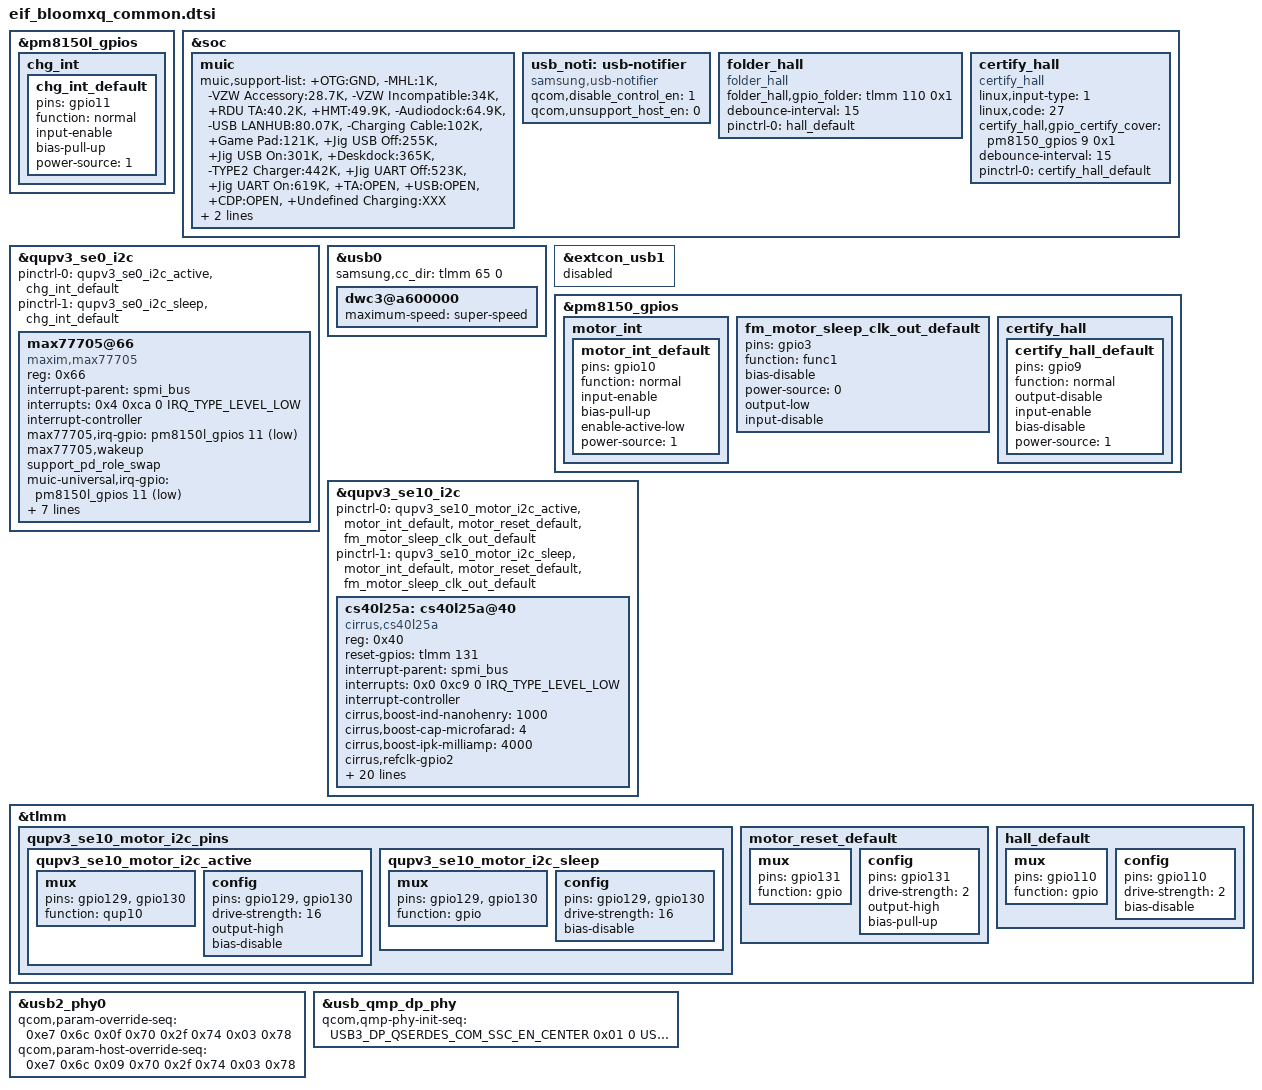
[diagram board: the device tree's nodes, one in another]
/* Copyright (c) 2019, The Linux Foundation. All rights reserved.
 *
 * This program is free software; you can redistribute it and/or modify
 * it under the terms of the GNU General Public License version 2 and
 * only version 2 as published by the Free Software Foundation.
 *
 * This program is distributed in the hope that it will be useful,
 * but WITHOUT ANY WARRANTY; without even the implied warranty of
 * MERCHANTABILITY or FITNESS FOR A PARTICULAR PURPOSE.  See the
 * GNU General Public License for more details.
 */

/* MUIC */
&pm8150l_gpios {
	chg_int {
		chg_int_default: chg_int_default {
			pins = "gpio11";
			function = "normal";
			input-enable;
			bias-pull-up;
			power-source = <1>;
		};
	};
};

&soc {
	muic {
		status = "okay";
		muic,support-list = "+OTG:GND",
				"-MHL:1K",
				"-VZW Accessory:28.7K",
				"-VZW Incompatible:34K",
				"+RDU TA:40.2K",
				"+HMT:49.9K",
				"-Audiodock:64.9K",
				"-USB LANHUB:80.07K",
				"-Charging Cable:102K",
				"+Game Pad:121K",
				"+Jig USB Off:255K",
				"+Jig USB On:301K",
				"+Deskdock:365K",
				"-TYPE2 Charger:442K",
				"+Jig UART Off:523K",
				"+Jig UART On:619K",
				"+TA:OPEN",
				"+USB:OPEN",
				"+CDP:OPEN",
				"+Undefined Charging:XXX";
		muic,afcmode-tx = /bits/ 8 <0x46>;
		muic,qc-hv = /bits/ 8 <0x9>;
	};

	usb_noti: usb-notifier {
		compatible = "samsung,usb-notifier";
		qcom,disable_control_en = <1>;
		qcom,unsupport_host_en = <0>;
	};

	folder_hall {
		compatible = "folder_hall";
		folder_hall,gpio_folder = <&tlmm 110 0x1>;
		debounce-interval = <15>;
		pinctrl-names = "default";
		pinctrl-0 = <&hall_default>;
	};

	certify_hall: certify_hall {
		status = "okay";
		compatible = "certify_hall";
		linux,input-type = <1>;
		linux,code = <27>;
		certify_hall,gpio_certify_cover = <&pm8150_gpios 9 0x1>;
		debounce-interval = <15>;
		pinctrl-names = "default";
		pinctrl-0 = <&certify_hall_default>;
	};
};

&qupv3_se0_i2c {
	status = "ok";

	pinctrl-0 = <&qupv3_se0_i2c_active &chg_int_default>;
	pinctrl-1 = <&qupv3_se0_i2c_sleep &chg_int_default>;

	max77705@66 {
		compatible = "maxim,max77705";
		reg = <0x66>;
		interrupt-parent = <&spmi_bus>;
		interrupts = <0x4 0xca 0 IRQ_TYPE_LEVEL_LOW>;
		interrupt-names = "max77705_irq";
		interrupt-controller;
		max77705,irq-gpio = <&pm8150l_gpios 11 0x01>;
		max77705,wakeup;
		support_pd_role_swap;
		muic-universal,irq-gpio = <&pm8150l_gpios 11 0x01>;
		muic-universal,chip_name = "maxim,max77705";
		muic,undefined_range;
		haptic,mode = <1>;
		haptic,divisor = <128>;
		max77705,detect-alalog-audio;
		max77705,bc1p2_retry_count = <2>;
		max77705,blocking_waterevent;
	};
};

/* USB */
&usb0 {
	samsung,cc_dir = <&tlmm 65 0>;
};

/* VIBRATOR */

/*disable extcon_usb1 because of pm8150_gpio 10 conflict*/
&extcon_usb1 {
	status = "disabled";
};

&pm8150_gpios {
	motor_int {
		motor_int_default: motor_int_default {
			pins = "gpio10";
			function = "normal";
			input-enable;
			bias-pull-up;
			enable-active-low;
			power-source = <1>;
		};
	};

	fm_motor_sleep_clk_out_default: fm_motor_sleep_clk_out_default {
		pins = "gpio3";
		function = "func1";
		bias-disable;
		power-source = <0>;
		output-low;
		input-disable;
	};
};

&qupv3_se10_i2c {
	status = "okay";
	pinctrl-names = "default", "sleep";
	pinctrl-0 = <&qupv3_se10_motor_i2c_active
			&motor_int_default &motor_reset_default
			&fm_motor_sleep_clk_out_default>;
	pinctrl-1 = <&qupv3_se10_motor_i2c_sleep &motor_int_default
			&motor_reset_default
			&fm_motor_sleep_clk_out_default>;

	cs40l25a: cs40l25a@40 {
		status = "okay";
		compatible = "cirrus,cs40l25a";
		reg = <0x40>;
		reset-gpios = <&tlmm 131 0>; // MOTOR_RST
		interrupt-parent = <&spmi_bus>;
		interrupts = <0x0 0xc9 0 IRQ_TYPE_LEVEL_LOW>; // MOTOR_INT
		interrupt-names = "default";
		interrupt-controller;
		cirrus,boost-ind-nanohenry = <1000>;
		cirrus,boost-cap-microfarad = <4>;
		cirrus,boost-ipk-milliamp = <4000>;
		cirrus,refclk-gpio2;
		cirrus,auto-recovery;
		cirrus,amp-gnd-stby;
		cirrus,hiber-enable;
		cirrus,gpio-indv-enable = <0x4>;
		cirrus,gpio1-mode = <1>;
		cirrus,boost-clab-millivolt = <4900>;
		cirrus,fw-id-remap = <0x1400cb>;
		cirrus,f0-default = <3538944>;
		samsung,vib_type = "LINEAR_1030";	// using cirrus motor IC and 1030 motor

		samsung,folder_type;

		samsung,dig_scale_close_short_duration = <0>;
		samsung,dig_scale_close_long_duration = <0>;
		samsung,dig_scale_open_short_duration = <0>;
		samsung,dig_scale_open_long_duration = <25>;
		samsung,dig_scale_open_long_duration_low_temp = <5>;
		samsung,dig_scale_open_long_duration_lower_temp = <0>;

		samsung,low_temp = <0>;
		samsung,lower_temp = <(-100)>;
	};
};

&tlmm {
	/delete-node/ qupv3_se10_i2c_pins;

	qupv3_se10_motor_i2c_pins: qupv3_se10_motor_i2c_pins {
		qupv3_se10_motor_i2c_active: qupv3_se10_motor_i2c_active {
			mux {
				pins = "gpio129", "gpio130";
				function = "qup10";
			};

			config {
				pins = "gpio129", "gpio130";
				drive-strength = <16>;
				output-high;
				bias-disable; /* No PULL */
			};
		};

		qupv3_se10_motor_i2c_sleep: qupv3_se10_motor_i2c_sleep {
			mux {
				pins = "gpio129", "gpio130";
				function = "gpio";
			};

			config {
				pins = "gpio129", "gpio130";
				drive-strength = <16>;
				bias-disable; /* No PULL */
			};
		};
	};

	motor_reset_default: motor_reset_default {
		mux {
			pins = "gpio131";
			function = "gpio";
		};
		config {
			pins = "gpio131";
			drive-strength = <2>;
			output-high;
			bias-pull-up;
		};
	};

	hall_default: hall_default {
		mux {
			pins = "gpio110";
			function = "gpio";
		};
		config {
			pins = "gpio110";
			drive-strength = <2>;
			bias-disable;
		};
	};
};

&pm8150_gpios {
	certify_hall {
		certify_hall_default: certify_hall_default {
			pins = "gpio9";
			function = "normal";
			output-disable;
			input-enable;
			bias-disable;
			power-source = <1>;
		};
	};
};

&usb0 {
	dwc3@a600000 {
		maximum-speed = "super-speed";
	};
};

#include <dt-bindings/phy/qcom,kona-qmp-usb3.h>

&usb2_phy0 {
	qcom,param-override-seq =
		<0xe7 0x6c
		 0x0f 0x70
		 0x2f 0x74
		 0x03 0x78>;
	qcom,param-host-override-seq =
		<0xe7 0x6c
		 0x09 0x70
		 0x2f 0x74
		 0x03 0x78>;
};

&usb_qmp_dp_phy {
		qcom,qmp-phy-init-seq =
			/* <reg_offset, value, delay> */
			<USB3_DP_QSERDES_COM_SSC_EN_CENTER 0x01 0
			USB3_DP_QSERDES_COM_SSC_PER1 0x31 0
			USB3_DP_QSERDES_COM_SSC_PER2 0x01 0
			USB3_DP_QSERDES_COM_SSC_STEP_SIZE1_MODE0 0xDE 0
			USB3_DP_QSERDES_COM_SSC_STEP_SIZE2_MODE0 0x07 0
			USB3_DP_QSERDES_COM_SSC_STEP_SIZE1_MODE1 0xDE 0
			USB3_DP_QSERDES_COM_SSC_STEP_SIZE2_MODE1 0x07 0
			USB3_DP_QSERDES_COM_SYSCLK_BUF_ENABLE 0x0A 0
			USB3_DP_QSERDES_COM_CMN_IPTRIM 0x20 0
			USB3_DP_QSERDES_COM_CP_CTRL_MODE0 0x06 0
			USB3_DP_QSERDES_COM_CP_CTRL_MODE1 0x06 0
			USB3_DP_QSERDES_COM_PLL_RCTRL_MODE0 0x16 0
			USB3_DP_QSERDES_COM_PLL_RCTRL_MODE1 0x16 0
			USB3_DP_QSERDES_COM_PLL_CCTRL_MODE0 0x36 0
			USB3_DP_QSERDES_COM_PLL_CCTRL_MODE1 0x36 0
			USB3_DP_QSERDES_COM_SYSCLK_EN_SEL 0x1A 0
			USB3_DP_QSERDES_COM_LOCK_CMP_EN 0x04 0
			USB3_DP_QSERDES_COM_LOCK_CMP1_MODE0 0x14 0
			USB3_DP_QSERDES_COM_LOCK_CMP2_MODE0 0x34 0
			USB3_DP_QSERDES_COM_LOCK_CMP1_MODE1 0x34 0
			USB3_DP_QSERDES_COM_LOCK_CMP2_MODE1 0x82 0
			USB3_DP_QSERDES_COM_DEC_START_MODE0 0x82 0
			USB3_DP_QSERDES_COM_DEC_START_MODE1 0x82 0
			USB3_DP_QSERDES_COM_DIV_FRAC_START1_MODE0 0xAB 0
			USB3_DP_QSERDES_COM_DIV_FRAC_START2_MODE0 0xEA 0
			USB3_DP_QSERDES_COM_DIV_FRAC_START3_MODE0 0x02 0
			USB3_DP_QSERDES_COM_DIV_FRAC_START1_MODE1 0xAB 0
			USB3_DP_QSERDES_COM_DIV_FRAC_START2_MODE1 0xEA 0
			USB3_DP_QSERDES_COM_DIV_FRAC_START3_MODE1 0x02 0
			USB3_DP_QSERDES_COM_VCO_TUNE_MAP 0x02 0
			USB3_DP_QSERDES_COM_VCO_TUNE1_MODE0 0x24 0
			USB3_DP_QSERDES_COM_VCO_TUNE1_MODE1 0x24 0
			USB3_DP_QSERDES_COM_VCO_TUNE2_MODE1 0x02 0
			USB3_DP_QSERDES_COM_HSCLK_SEL 0x01 0
			USB3_DP_QSERDES_COM_CORECLK_DIV_MODE1 0x08 0
			USB3_DP_QSERDES_COM_BIN_VCOCAL_CMP_CODE1_MODE0 0xCA 0
			USB3_DP_QSERDES_COM_BIN_VCOCAL_CMP_CODE2_MODE0 0x1E 0
			USB3_DP_QSERDES_COM_BIN_VCOCAL_CMP_CODE1_MODE1 0xCA 0
			USB3_DP_QSERDES_COM_BIN_VCOCAL_CMP_CODE2_MODE1 0x1E 0
			USB3_DP_QSERDES_COM_BIN_VCOCAL_HSCLK_SEL 0x11 0
			USB3_DP_QSERDES_TXA_RES_CODE_LANE_TX 0x60 0
			USB3_DP_QSERDES_TXA_RES_CODE_LANE_RX 0x60 0
			USB3_DP_QSERDES_TXA_RES_CODE_LANE_OFFSET_TX 0x11 0
			USB3_DP_QSERDES_TXA_RES_CODE_LANE_OFFSET_RX 0x02 0
			USB3_DP_QSERDES_TXA_LANE_MODE_1 0xD5 0
			USB3_DP_QSERDES_TXA_RCV_DETECT_LVL_2 0x12 0
			USB3_DP_QSERDES_TXA_PI_QEC_CTRL 0x40 0
			USB3_DP_QSERDES_RXA_UCDR_SO_GAIN 0x06 0
			USB3_DP_QSERDES_RXA_UCDR_FASTLOCK_FO_GAIN 0x2F 0
			USB3_DP_QSERDES_RXA_UCDR_SO_SATURATION_AND_ENABLE 0x7F 0
			USB3_DP_QSERDES_RXA_UCDR_FASTLOCK_COUNT_LOW 0xFF 0
			USB3_DP_QSERDES_RXA_UCDR_FASTLOCK_COUNT_HIGH 0x0F 0
			USB3_DP_QSERDES_RXA_UCDR_PI_CONTROLS 0x99 0
			USB3_DP_QSERDES_RXA_UCDR_SB2_THRESH1 0x04 0
			USB3_DP_QSERDES_RXA_UCDR_SB2_THRESH2 0x08 0
			USB3_DP_QSERDES_RXA_UCDR_SB2_GAIN1 0x05 0
			USB3_DP_QSERDES_RXA_UCDR_SB2_GAIN2 0x05 0
			USB3_DP_QSERDES_RXA_VGA_CAL_CNTRL1 0x54 0
			USB3_DP_QSERDES_RXA_VGA_CAL_CNTRL2 0x0C 0
			USB3_DP_QSERDES_RXA_RX_EQU_ADAPTOR_CNTRL2 0x0F 0
			USB3_DP_QSERDES_RXA_RX_EQU_ADAPTOR_CNTRL3 0x4A 0
			USB3_DP_QSERDES_RXA_RX_EQU_ADAPTOR_CNTRL4 0x0A 0
			USB3_DP_QSERDES_RXA_RX_IDAC_TSETTLE_LOW 0xC0 0
			USB3_DP_QSERDES_RXA_RX_IDAC_TSETTLE_HIGH 0x00 0
			USB3_DP_QSERDES_RXA_RX_EQ_OFFSET_ADAPTOR_CNTRL1 0x77 0
			USB3_DP_QSERDES_RXA_SIGDET_CNTRL 0x04 0
			USB3_DP_QSERDES_RXA_SIGDET_DEGLITCH_CNTRL 0x0E 0
			USB3_DP_QSERDES_RXA_RX_MODE_00_LOW 0xFF 0
			USB3_DP_QSERDES_RXA_RX_MODE_00_HIGH 0x7F 0
			USB3_DP_QSERDES_RXA_RX_MODE_00_HIGH2 0x7F 0
			USB3_DP_QSERDES_RXA_RX_MODE_00_HIGH3 0xFF 0
			USB3_DP_QSERDES_RXA_RX_MODE_00_HIGH4 0x97 0
			USB3_DP_QSERDES_RXA_RX_MODE_01_LOW 0xDC 0
			USB3_DP_QSERDES_RXA_RX_MODE_01_HIGH 0xDC 0
			USB3_DP_QSERDES_RXA_RX_MODE_01_HIGH2 0x5C 0
			USB3_DP_QSERDES_RXA_RX_MODE_01_HIGH3 0x7B 0
			USB3_DP_QSERDES_RXA_RX_MODE_01_HIGH4 0xB6 0
			USB3_DP_QSERDES_RXA_DFE_EN_TIMER 0x04 0
			USB3_DP_QSERDES_RXA_DFE_CTLE_POST_CAL_OFFSET 0x38 0
			USB3_DP_QSERDES_RXA_AUX_DATA_TCOARSE_TFINE 0xA0 0
			USB3_DP_QSERDES_RXA_DCC_CTRL1 0x0C 0
			USB3_DP_QSERDES_RXA_GM_CAL 0x1F 0
			USB3_DP_QSERDES_RXA_VTH_CODE 0x10 0
			USB3_DP_QSERDES_TXB_RES_CODE_LANE_TX 0x60 0
			USB3_DP_QSERDES_TXB_RES_CODE_LANE_RX 0x60 0
			USB3_DP_QSERDES_TXB_RES_CODE_LANE_OFFSET_TX 0x11 0
			USB3_DP_QSERDES_TXB_RES_CODE_LANE_OFFSET_RX 0x02 0
			USB3_DP_QSERDES_TXB_LANE_MODE_1 0xD5 0
			USB3_DP_QSERDES_TXB_RCV_DETECT_LVL_2 0x12 0
			USB3_DP_QSERDES_TXB_PI_QEC_CTRL 0x54 0
			USB3_DP_QSERDES_RXB_UCDR_SO_GAIN 0x06 0
			USB3_DP_QSERDES_RXB_UCDR_FASTLOCK_FO_GAIN 0x2F 0
			USB3_DP_QSERDES_RXB_UCDR_SO_SATURATION_AND_ENABLE 0x7F 0
			USB3_DP_QSERDES_RXB_UCDR_FASTLOCK_COUNT_LOW 0xFF 0
			USB3_DP_QSERDES_RXB_UCDR_FASTLOCK_COUNT_HIGH 0x0F 0
			USB3_DP_QSERDES_RXB_UCDR_PI_CONTROLS 0x99 0
			USB3_DP_QSERDES_RXB_UCDR_SB2_THRESH1 0x04 0
			USB3_DP_QSERDES_RXB_UCDR_SB2_THRESH2 0x08 0
			USB3_DP_QSERDES_RXB_UCDR_SB2_GAIN1 0x05 0
			USB3_DP_QSERDES_RXB_UCDR_SB2_GAIN2 0x05 0
			USB3_DP_QSERDES_RXB_VGA_CAL_CNTRL1 0x54 0
			USB3_DP_QSERDES_RXB_VGA_CAL_CNTRL2 0x0C 0
			USB3_DP_QSERDES_RXB_RX_EQU_ADAPTOR_CNTRL2 0x0F 0
			USB3_DP_QSERDES_RXB_RX_EQU_ADAPTOR_CNTRL3 0x4A 0
			USB3_DP_QSERDES_RXB_RX_EQU_ADAPTOR_CNTRL4 0x0A 0
			USB3_DP_QSERDES_RXB_RX_IDAC_TSETTLE_LOW 0xC0 0
			USB3_DP_QSERDES_RXB_RX_IDAC_TSETTLE_HIGH 0x00 0
			USB3_DP_QSERDES_RXB_RX_EQ_OFFSET_ADAPTOR_CNTRL1 0x77 0
			USB3_DP_QSERDES_RXB_SIGDET_CNTRL 0x04 0
			USB3_DP_QSERDES_RXB_SIGDET_DEGLITCH_CNTRL 0x0E 0
			USB3_DP_QSERDES_RXB_RX_MODE_00_LOW 0x7F 0
			USB3_DP_QSERDES_RXB_RX_MODE_00_HIGH 0xFF 0
			USB3_DP_QSERDES_RXB_RX_MODE_00_HIGH2 0x7F 0
			USB3_DP_QSERDES_RXB_RX_MODE_00_HIGH3 0xFF 0
			USB3_DP_QSERDES_RXB_RX_MODE_00_HIGH4 0x97 0
			USB3_DP_QSERDES_RXB_RX_MODE_01_LOW 0xDC 0
			USB3_DP_QSERDES_RXB_RX_MODE_01_HIGH 0xDC 0
			USB3_DP_QSERDES_RXB_RX_MODE_01_HIGH2 0x5C 0
			USB3_DP_QSERDES_RXB_RX_MODE_01_HIGH3 0x7B 0
			USB3_DP_QSERDES_RXB_RX_MODE_01_HIGH4 0xB6 0
			USB3_DP_QSERDES_RXB_DFE_EN_TIMER 0x04 0
			USB3_DP_QSERDES_RXB_DFE_CTLE_POST_CAL_OFFSET 0x38 0
			USB3_DP_QSERDES_RXB_AUX_DATA_TCOARSE_TFINE 0xA0 0
			USB3_DP_QSERDES_RXB_DCC_CTRL1 0x0C 0
			USB3_DP_QSERDES_RXB_GM_CAL 0x1F 0
			USB3_DP_QSERDES_RXB_VTH_CODE 0x10 0
			USB3_DP_PCS_LOCK_DETECT_CONFIG1 0xD0 0
			USB3_DP_PCS_LOCK_DETECT_CONFIG2 0x07 0
			USB3_DP_PCS_LOCK_DETECT_CONFIG3 0x20 0
			USB3_DP_PCS_LOCK_DETECT_CONFIG6 0x13 0
			USB3_DP_PCS_REFGEN_REQ_CONFIG1 0x21 0
			USB3_DP_PCS_RX_SIGDET_LVL 0xA9 0
			USB3_DP_PCS_CDR_RESET_TIME 0x0A 0
			USB3_DP_PCS_ALIGN_DETECT_CONFIG1 0x88 0
			USB3_DP_PCS_ALIGN_DETECT_CONFIG2 0x13 0
			USB3_DP_PCS_PCS_TX_RX_CONFIG 0x0C 0
			USB3_DP_PCS_EQ_CONFIG1 0x4B 0
			USB3_DP_PCS_EQ_CONFIG5 0x10 0
			USB3_DP_PCS_USB3_LFPS_DET_HIGH_COUNT_VAL 0xF8 0
			USB3_DP_PCS_USB3_RXEQTRAINING_DFE_TIME_S2 0x07 0
			0xffffffff 0xffffffff 0x00>;
};
